# STC32G144K246 register map
Vendor: STC; File version: 2.0
Registers are 8-bit, read-write, no defined reset value unless marked. A register's access mark holds for its fields unless they carry their own. Offsets are from the block's base; [hi:lo] are bit positions.

## Clock — 时钟源、分频、振荡器和 PLL
Base 0x007EFE00
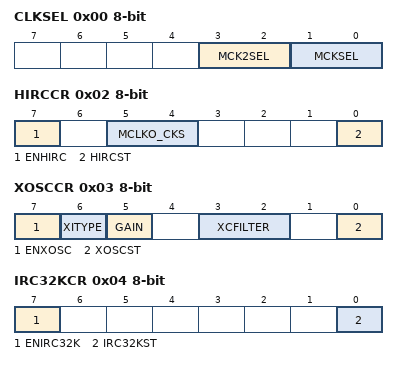
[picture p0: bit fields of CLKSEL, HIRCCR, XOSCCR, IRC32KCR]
0x00 CLKSEL — 时钟选择寄存器
  [3:2] MCK2SEL — 主时钟源选择
    0=MCKSEL 选择的时钟源; 1=内部HPLL1 输出/2; 2=内部HPLL2 输出/2; 3=内部48MHz 高速IRC
  [1:0] MCKSEL — 主时钟源选择
    0=内部高精度IRC; 1=外部高速晶振; 2=外部32KHz 晶振; 3=内部32KHz 低速IRC
0x01 CLKDIV — 时钟分频寄存器
  [7:0] CLKDIV — 主时钟分频系数。系统时钟SYSCLK 是对主时钟MCLK 进行分频后的时钟信号。
0x02 HIRCCR — 内部高速振荡器控制寄存器
  [7] ENHIRC — 内部高速高精度IRC 使能位
    0=关闭内部高精度IRC; 1=使能内部高精度IRC
  [5:4] MCLKO_CKS — 时钟输出的时钟源选择（此位只写）
    0=关闭主时钟输出; 1=输出系统时钟; 2=输出内部高速HIRC 时钟; 3=输出滤波后的内部高速HIRC 时钟
  [0] HIRCST — 内部高速高精度IRC 频率稳定标志位。（只读位） 当内部的IRC 从停振状态开始使能后，必须经过一段时间，振荡器的频率才会稳定，当振荡器频率 稳定后，时钟控制器会自动将HIRCST 标志位置1。所以当用户程序需要将时钟切换到使用内部IRC 时，首先必须设置ENHIRC=1 使能振荡器，然后一直查询振
0x03 XOSCCR — 外部晶振控制寄存器
  [7] ENXOSC — 外部晶体振荡器使能位
    0=关闭外部晶体振荡器; 1=使能外部晶体振荡器
  [6] XITYPE — 外部时钟源类型
    0=外部时钟源是外部时钟信号（或有源晶振）。信号源只需连接单片机的XTALI（P1.7），此时P1.6; 1=外部时钟源是晶体振荡器。信号源连接单片机的XTALI（P1.7）和XTALO（P1.6）
  [5] GAIN — 外部晶体振荡器振荡增益控制位
    0=关闭振荡增益（低增益）; 1=使能振荡增益（高增益）
  [3:2] XCFILTER — 外部晶体振荡器抗干扰控制寄存器
  [0] XOSCST — 外部晶体振荡器频率稳定标志位。（只读位） 当外部晶体振荡器从停振状态开始使能后，必须经过一段时间，振荡器的频率才会稳定，当振荡器 频率稳定后，时钟控制器会自动将XOSCST 标志位置1。所以当用户程序需要将时钟切换到使用外 部晶体振荡器时，首先必须设置ENXOSC=1 使能振荡器，然后一直查询振荡器
0x04 IRC32KCR — 内部低速振荡器控制寄存器
  [7] ENIRC32K — 内部低速IRC 使能位
    0=关闭内部低速IRC; 1=使能内部低速IRC
  [0] IRC32KST — 内部低速IRC 频率稳定标志位。（只读位） 当内部低速IRC 从停振状态开始使能后，必须经过一段时间，振荡器的频率才会稳定，当振荡器频 率稳定后，时钟控制器会自动将IRC32KST 标志位置1。所以当用户程序需要将时钟切换到使用内 部低速IRC 时，首先必须设置ENIRC32K=1 使能振荡器，然后
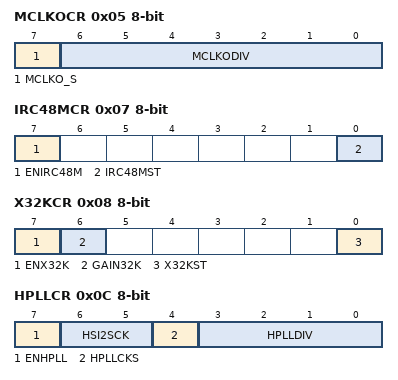
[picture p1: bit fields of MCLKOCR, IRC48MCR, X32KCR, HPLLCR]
0x05 MCLKOCR — 主时钟输出控制寄存器
  [7] MCLKO_S — 系统时钟输出管脚选择
    0=系统时钟分频输出到P5.4 口; 1=系统时钟分频输出到P1.6 口
  [6:0] MCLKODIV — 主时钟输出分频系数
0x07 IRC48MCR — 内部48M振荡器控制寄存器
  [7] ENIRC48M — 内部48M 高速IRC 使能位
    0=关闭内部48M 高速IRC; 1=使能内部48M 高速IRC
  [0] IRC48MST — 内部48M 高速IRC 频率稳定标志位。（只读位） 当内部48M 高速IRC 从停振状态开始使能后，必须经过一段时间，振荡器的频率才会稳定，当振荡 器频率稳定后，时钟控制器会自动将IRC48MST 标志位置1。所以当用户程序需要将时钟切换到使 用内部48M 高速IRC 时，首先必须设置ENIRC48
0x08 X32KCR — 外部32K晶振控制寄存器
  [7] ENX32K — 外部32K 晶体振荡器使能位
    0=关闭外部32K 晶体振荡器; 1=使能外部32K 晶体振荡器
  [6] GAIN32K — 外部32K 晶体振荡器振荡增益控制位
    0=关闭32K 振荡增益（低增益）; 1=使能32K 振荡增益（高增益）
  [0] X32KST — 外部32K 晶体振荡器频率稳定标志位。（只读位）
0x0C HPLLCR — 高速PLL控制寄存器
  [7] ENHPLL — 高速PLL 使能位
    0=关闭HPLL; 1=使能HPLL
  [6:5] HSI2SCK — 两组高速I2S 时钟选择
  [4] HPLLCKS — 高速PLL 输入时钟源选择
    0=内部基本时钟（BASECLK）; 1=内部48M 的IRC 时钟
  [3:0] HPLLDIV — 高速PLL 锁频的除频数（倍频数）
0x0D HPLLPDIV — 高速PLL预分频寄存器
  [7:0] HPLL_PREDIV — 尚未自动匹配到此字段的独立说明；请查看下方章节说明。
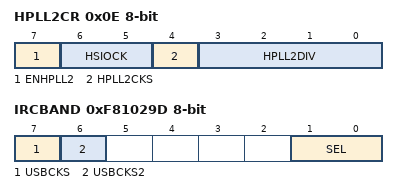
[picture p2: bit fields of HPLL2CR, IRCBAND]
0x0E HPLL2CR — 高速PLL2控制寄存器
  [7] ENHPLL2 — 高速PLL2 使能位
    0=关闭HPLL2; 1=使能HPLL2
  [6:5] HSIOCK — 两组高速外设时钟选择
  [4] HPLL2CKS — 高速PLL2 输入时钟源选择
    0=内部基本时钟（BASECLK）; 1=内部48M 的IRC 时钟
  [3:0] HPLL2DIV — 高速PLL2 锁频的除频数（倍频数）
0x0F HPLL2PDIV — 高速PLL2预分频寄存器
  [7:0] HPLL2_PREDIV — 尚未自动匹配到此字段的独立说明；请查看下方章节说明。
0xF81029D IRCBAND ro — IRC频段选择检测
  [7] USBCKS — 尚未自动匹配到此字段的独立说明；请查看下方章节说明。
  [6] USBCKS2 — 尚未自动匹配到此字段的独立说明；请查看下方章节说明。
  [1:0] SEL — 频段选择
    0=选择10MHz 频段; 1=选择27MHz 频段; 2=选择44MHz 频段; 3=选择72MHz 频段

## ClockCalibration — 内部 IRC 校准与追频
Base 0x007EFDA8
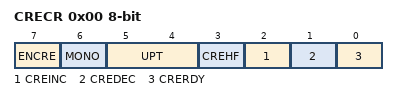
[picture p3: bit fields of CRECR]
0x00 CRECR ro — CRE控制寄存器
  [7] ENCRE — CRE模块控制位
    0=关闭CRE 模块。; 1=使能CRE 模块。
  [6] MONO — 自动校准步幅控制
    0=单步模式。每个校准周期，硬件自动将IRTRIM 递增或递减1。; 1=双步模式。每个校准周期，硬件自动将IRTRIM 递增或递减2。
  [5:4] UPT — CRE 校准周期选择
    0=1ms; 1=4ms; 2=32ms; 3=64ms
  [3] CREHF — 高频模式选择
    0=低频模式（目标频率小于或等于50MHz）。; 1=高频模式（目标频率大于50MHz）。
  [2] CREINC — CRE校准正处于上调状态。只读位。
  [1] CREDEC — CRE校准正处于下调状态。只读位。
  [0] CRERDY — CRE校准完成状态。只读位。
    0=CRE 校准功能未启动或者未校准完成。; 1=CRE 校准已完成。
0x01 CRECNTH ro — CRE校准目标寄存器
  [7:0] CNT — 尚未自动匹配到此字段的独立说明；请查看下方章节说明。
0x02 CRECNTL ro — CRE校准目标寄存器
  [7:0] CNT — 尚未自动匹配到此字段的独立说明；请查看下方章节说明。
0x03 CRERES ro — CRE分辨率控制寄存器
0x04 CRECFG ro

## PowerReset — 电源管理、低压和复位来源
Base 0x007EFE99
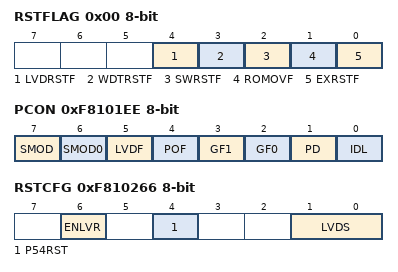
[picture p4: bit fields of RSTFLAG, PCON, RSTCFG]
0x00 RSTFLAG ro — 复位标志寄存器
  [4] LVDRSTF — LVD 低压复位标志 读0：无意义 读1：当前的复位是由LVD 低压复位所触发（上电复位默认值为1） 写0：无效果 写1：清除LVDRST 标志位
  [3] WDTRSTF — 看门狗复位标志 读0：无意义（上电复位默认值为0） 读1：当前的复位是由看门狗溢出所触发 写0：无效果 写1：清除WDTRST 标志位
  [2] SWRSTF — 软复位标志 读0：无意义 读1：当前的复位是由软件写SWRST（IAP_CONTR.5）所触发（用户程序复位默认值为1） 写0：无效果 写1：清除SWRST 标志位
  [1] ROMOVF — 代码区溢出标志 读0：无意义（上电复位默认值为0） 读1：当前的复位是由于CPU 执行代码到非程序区导致的代码区溢出所触发 写0：无效果 写1：清除ROMOV 标志位
  [0] EXRSTF — 外部复位标志 读0：无意义（上电复位默认值为0） 读1：当前的复位是外部复位脚（P5.4/RST）被拉低所触发 写0：无效果 写1：清除EXRST 标志位
0xF8101EE PCON ro — 电源控制寄存器
  [7] SMOD — 串口1 波特率控制位
    0=SYSclk波特率=𝟔𝟒; 1=SYSclk波特率=𝟑𝟐
  [6] SMOD0 — 帧错误检测控制位
    0=无帧错检测功能; 1=使能帧错误检测功能。此时SCON 的SM0/FE 为FE 功能，即为帧错误检测标志位。
  [5] LVDF — 低压检测标志位。当系统检测到低压事件时，硬件自动将此位置1，此位需要用户软件清零。 LVD 低压检测有低压检测门槛电压可选： 2.0V/2.4V/2.7V/3.0V，误差±1%。 LVD 低压检测在ISP 烧录时默认设置是低压即复位。 当允许LVD 低压检测复位，并且电压低到指定的LVD 复位门槛电
  [4] POF — 上电复位标志位。上电复位硬件自动置1。需要软件清0，硬件不会自动清0。 当 MCU-Vcc 电压 低于1.65V±10% 以下时，STC8/STC32/AI8051U 系列 MCU 都会掉电复位。 当 MCU-Vcc 电压从低于 1.65V±10% 以下往上爬升，电压爬升到比1.65V 高后， 硬件
  [3] GF1 — 尚未自动匹配到此字段的独立说明；请查看下方章节说明。
  [2] GF0 — 尚未自动匹配到此字段的独立说明；请查看下方章节说明。
  [1] PD — 主时钟停振/省电模式控制位
    0=无影响; 1=单片机进入主时钟停振/省电模式，CPU 以及全部外设均停止工作。唤醒后硬件自动清零。
  [0] IDL — IDLE（空闲）模式控制位
    0=无影响; 1=单片机进入IDLE 模式，只有CPU 停止工作，其他外设依然在运行。唤醒后硬件自动清零
0xF810266 RSTCFG ro — 复位配置寄存器
  [6] ENLVR — 低压复位控制位
    0=禁止低压复位。当系统检测到低压事件时，会产生低压中断; 1=使能低压复位。当系统检测到低压事件时，自动复位
  [4] P54RST — 尚未自动匹配到此字段的独立说明；请查看下方章节说明。
  [1:0] LVDS — 低压检测门槛电压设置
    0=2.0V; 1=2.4V; 2=2.7V; 3=3.0V
